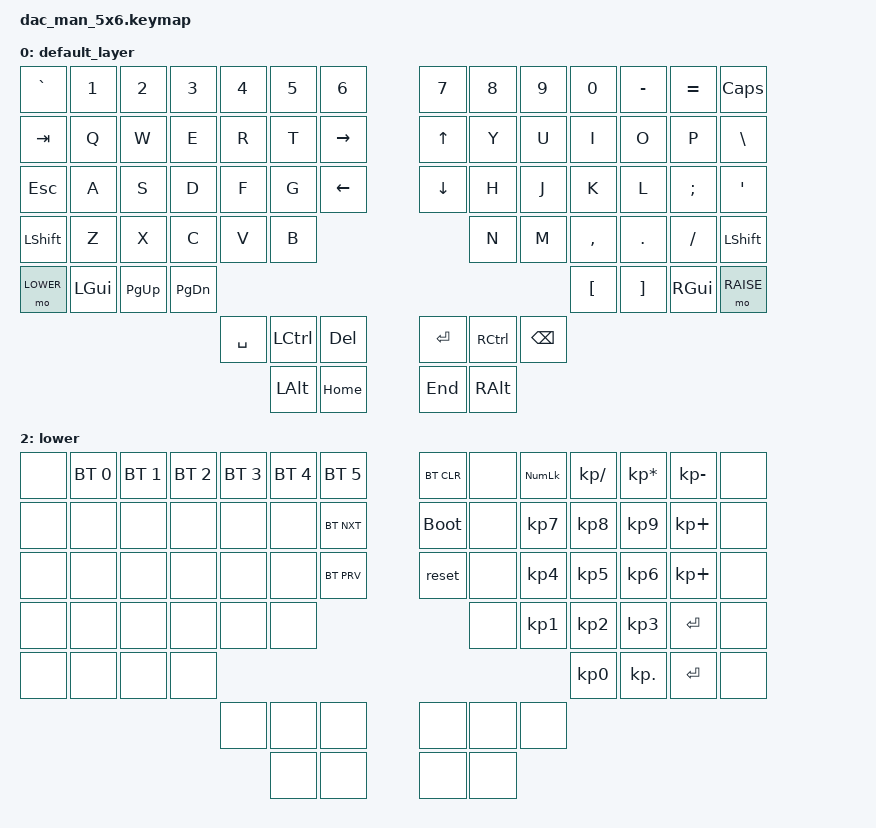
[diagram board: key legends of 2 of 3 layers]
#include <behaviors.dtsi>
#include <dt-bindings/zmk/keys.h>
#include <dt-bindings/zmk/bt.h>

#define DEFAULT 0
#define RAISE   1
#define LOWER   2

/ {
    keymap {
        compatible = "zmk,keymap";
        default_layer {
            bindings = <
&kp GRAVE   &kp N1     &kp N2    &kp N3     &kp N4     &kp N5   &kp N6                 &kp N7      &kp N8     &kp N9     &kp N0     &kp MINUS  &kp EQUAL      &kp CAPS
&kp TAB     &kp Q      &kp W     &kp E      &kp R      &kp T    &kp RIGHT              &kp UP      &kp Y      &kp U      &kp I      &kp O      &kp P          &kp BSLH
&kp ESC     &kp A      &kp S     &kp D      &kp F      &kp G    &kp LEFT               &kp DOWN    &kp H      &kp J      &kp K      &kp L      &kp SEMI       &kp SQT
&kp LSHIFT  &kp Z      &kp X     &kp C      &kp V      &kp B                                       &kp N      &kp M      &kp COMMA  &kp DOT    &kp FSLH       &kp LSHIFT
&mo LOWER   &kp LGUI   &kp PG_UP &kp PG_DN                                                                               &kp LBKT   &kp RBKT   &kp RGUI       &mo RAISE
                                            &kp SPACE &kp LCTRL &kp DEL                &kp ENTER  &kp RCTRL   &kp BSPC   
                                                      &kp LALT  &kp HOME               &kp END    &kp RALT
            >;
        };
        raise {
            bindings = <
&none   &kp F1   &kp F2   &kp F3    &kp F4    &kp F5  &kp F6       &kp F7   &kp F8     &kp F9     &kp F10    &kp F11    &kp F12    &none
&none   &none    &none    &none     &none     &none   &none        &none    &none      &none      &none      &none      &none      &none
&none   &none    &none    &none     &none     &none   &none        &none    &none      &none      &none      &none      &none      &none
&none   &none    &none    &none     &none     &none                &none    &none      &none      &none      &none      &none      &none
&none   &none    &none    &none                                                                   &none      &none      &none      &none
                                    &none     &none   &none        &none    &none      &none
                                              &none   &none        &none    &none
            >;
        };
        lower {
            bindings = <
&none   &bt BT_SEL 0   &bt BT_SEL 1   &bt BT_SEL 2    &bt BT_SEL 3    &bt BT_SEL 4   &bt BT_SEL 5       &bt BT_CLR   &none    &kp KP_NLCK  &kp KP_SLASH     &kp KP_MULTIPLY &kp KP_MINUS    &none
&none   &none          &none          &none           &none           &none          &bt BT_NXT         &bootloader  &none    &kp KP_N7    &kp KP_N8        &kp KP_N9       &kp KP_PLUS     &none
&none   &none          &none          &none           &none           &none          &bt BT_PRV         &reset       &none    &kp KP_N4    &kp KP_N5        &kp KP_N6       &kp KP_PLUS     &none
&none   &none          &none          &none           &none           &none                                          &none    &kp KP_N1    &kp KP_N2        &kp KP_N3       &kp ENTER       &none
&none   &none          &none          &none                                                                                                &kp KP_N0        &kp KP_DOT      &kp ENTER       &none
                                                      &none           &none          &none              &none        &none    &none
                                                                      &none          &none              &none        &none
            >;
        };
   };
};

